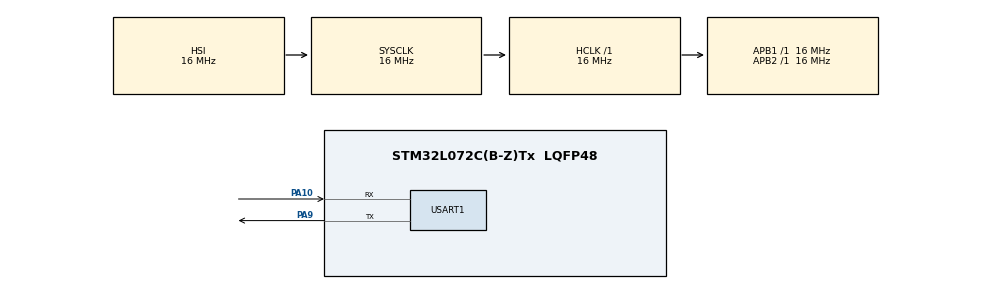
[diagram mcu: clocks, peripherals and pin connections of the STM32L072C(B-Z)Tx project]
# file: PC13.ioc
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Mcu.Family=STM32L0
Mcu.Name=STM32L072C(B-Z)Tx
Mcu.Package=LQFP48
PA10.Mode=Asynchronous
PA10.Signal=USART1_RX
PA9.Mode=Asynchronous
PA9.Signal=USART1_TX
PH0-OSC_IN.Mode=HSE-External-Oscillator
PH0-OSC_IN.Signal=RCC_OSC_IN
PH1-OSC_OUT.Mode=HSE-External-Oscillator
PH1-OSC_OUT.Signal=RCC_OSC_OUT
ProjectManager.HeapSize=0x200
ProjectManager.StackSize=0x400
ProjectManager.TargetToolchain=MDK-ARM V5
RCC.48MEnable=false
RCC.ADCEnable=false
RCC.AHBFreq_Value=16000000
RCC.APB1Freq_Value=16000000
RCC.APB1TimFreq_Value=16000000
RCC.APB2Freq_Value=16000000
RCC.APB2TimFreq_Value=16000000
RCC.ClockTypeHCLK=RCC_CLOCKTYPE_HCLK
RCC.ClockTypePCLK1=RCC_CLOCKTYPE_PCLK1
RCC.ClockTypePCLK2=RCC_CLOCKTYPE_PCLK2
RCC.ClockTypeSysClk=RCC_CLOCKTYPE_SYSCLK
RCC.EnableCSSLSE=false
RCC.EnableHSE=true
RCC.EnableHSELCDDevisor=false
RCC.EnableHSERTCDevisor=false
RCC.EnableLSE=false
RCC.EnableLSERTC=false
RCC.EnbaleCSS=false
RCC.HCLKFreq_Value=16000000
RCC.HSE_VALUE=8000000
RCC.HSI16State=RCC_HSI_ON
RCC.HSI16_VALUE=16000000
RCC.HSI48State=RCC_HSI48_OFF
RCC.HSI48_VALUE=48000000
RCC.HSI_VALUE=16000000
RCC.I2C1Enable=false
RCC.IWDGEnable=false
RCC.LCDEnable=false
RCC.LPTIMEnable=false
RCC.LPUARTEnable=false
RCC.LSE_VALUE=32768
RCC.LSIState=RCC_LSI_OFF
RCC.MCOEnable=false
RCC.MSI_VALUE=2097000
RCC.PLLSource=RCC_PLLSOURCE_HSI
RCC.PLLState=RCC_PLL_OFF
RCC.RCC_PERIPHCLK_USART1Var=RCC_PERIPHCLK_USART1
RCC.RNGEnable=false
RCC.RTCEnable=false
RCC.SYSCLKFreq_VALUE=16000000
RCC.SYSCLKSource=RCC_SYSCLKSOURCE_HSI
RCC.USART1Enable=true
RCC.USART2Enable=false
RCC.USBEnable=false
RCC.VCOOutputFreq_Value=48000000
USART1.HwFlowCtl-Asynchronous=UART_HWCONTROL_NONE
USART1.VirtualMode-Asynchronous=VM_ASYNC
board=PC13

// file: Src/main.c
/**
  ******************************************************************************
  * File Name          : main.c
  * Description        : Main program body
  ******************************************************************************
  *
  * COPYRIGHT(c) 2017 STMicroelectronics
  *
  * Redistribution and use in source and binary forms, with or without modification,
  * are permitted provided that the following conditions are met:
  *   1. Redistributions of source code must retain the above copyright notice,
  *      this list of conditions and the following disclaimer.
  *   2. Redistributions in binary form must reproduce the above copyright notice,
  *      this list of conditions and the following disclaimer in the documentation
  *      and/or other materials provided with the distribution.
  *   3. Neither the name of STMicroelectronics nor the names of its contributors
  *      may be used to endorse or promote products derived from this software
  *      without specific prior written permission.
  *
  * THIS SOFTWARE IS PROVIDED BY THE COPYRIGHT HOLDERS AND CONTRIBUTORS "AS IS"
  * AND ANY EXPRESS OR IMPLIED WARRANTIES, INCLUDING, BUT NOT LIMITED TO, THE
  * IMPLIED WARRANTIES OF MERCHANTABILITY AND FITNESS FOR A PARTICULAR PURPOSE ARE
  * DISCLAIMED. IN NO EVENT SHALL THE COPYRIGHT HOLDER OR CONTRIBUTORS BE LIABLE
  * FOR ANY DIRECT, INDIRECT, INCIDENTAL, SPECIAL, EXEMPLARY, OR CONSEQUENTIAL
  * DAMAGES (INCLUDING, BUT NOT LIMITED TO, PROCUREMENT OF SUBSTITUTE GOODS OR
  * SERVICES; LOSS OF USE, DATA, OR PROFITS; OR BUSINESS INTERRUPTION) HOWEVER
  * CAUSED AND ON ANY THEORY OF LIABILITY, WHETHER IN CONTRACT, STRICT LIABILITY,
  * OR TORT (INCLUDING NEGLIGENCE OR OTHERWISE) ARISING IN ANY WAY OUT OF THE USE
  * OF THIS SOFTWARE, EVEN IF ADVISED OF THE POSSIBILITY OF SUCH DAMAGE.
  *
  ******************************************************************************
  */
#include "main.h"
#include "stm32l0xx_hal.h"
#include "usart.h"
#include "gpio.h"

/* USER CODE BEGIN Includes */

#include "user_standby.h"

/* USER CODE END Includes */

/* USER CODE BEGIN PV */
/* Private variables ---------------------------------------------------------*/
#ifdef __GNUC__
  /* With GCC/RAISONANCE, small printf (option LD Linker->Libraries->Small printf
     set to 'Yes') calls __io_putchar() */
  #define PUTCHAR_PROTOTYPE int __io_putchar(int ch)
#else
  #define PUTCHAR_PROTOTYPE int fputc(int ch, FILE *f)
#endif /* __GNUC__ */

 /**
  * @brief  Retargets the C library printf function to the USART.
  * @param  None
  * @retval None
  */
PUTCHAR_PROTOTYPE
{
  /* Place your implementation of fputc here */
  /* e.g. write a character to the USART */
  HAL_UART_Transmit(&huart1, (uint8_t *)&ch, 1, 0xFFFF);  ///不需要库原因：从速度考虑直接使用寄存器更好
  return 1;
}

/* USER CODE END PV */

void SystemClock_Config(void);
void Error_Handler(void);

/* USER CODE BEGIN PFP */
/* Private function prototypes -----------------------------------------------*/

/* USER CODE END PFP */

int main(void)
{

  /* MCU Configuration----------------------------------------------------------*/

  /* Reset of all peripherals, Initializes the Flash interface and the Systick. */
  HAL_Init();

  /* Configure the system clock */
  SystemClock_Config();

  /* Initialize all configured peripherals */
  MX_GPIO_Init();
  MX_USART1_UART_Init();

  StandbyExitMode( );

  /* USER CODE BEGIN 2 */
  printf("hello world\r\n");
 /* 检测系统是否是从待机模式启动的 */
  if (__HAL_PWR_GET_FLAG(PWR_FLAG_SB) != RESET)
  {
    printf("待机唤醒复位\n");

		if(StandbyCheckPwrkey())  ///读IO信息，无触发中断
		{
			//StandbyInit( );
		  printf("开机\r\n");
			/* 清除待机标志位 */
			__HAL_PWR_CLEAR_FLAG(PWR_FLAG_SB);
//			StandbyExitMode( );  ///中断唤醒后再次初始化PC13外部中断
		}else
		{
				printf("继续休眠\r\n");
			 	StandbyEnterMode( );
		}
  }
  else if(__HAL_RCC_GET_FLAG(RCC_FLAG_SFTRST))
  {
    printf("\n软件复位不重置\n");
   	__HAL_RCC_CLEAR_RESET_FLAGS();
  }
	else
	{
		printf("系统上电休眠\r\n");
		StandbyEnterMode( );
	}

  /* USER CODE END 2 */

  /* Infinite loop */
  while (1)
  {

  /* USER CODE BEGIN 3 */
		printf("hello world123\r\n");
		HAL_Delay(500);

  }
  /* USER CODE END 3 */

}

/** System Clock Configuration
*/
void SystemClock_Config(void)
{

  RCC_OscInitTypeDef RCC_OscInitStruct;
  RCC_ClkInitTypeDef RCC_ClkInitStruct;
  RCC_PeriphCLKInitTypeDef PeriphClkInit;

    /**Configure the main internal regulator output voltage
    */
  __HAL_PWR_VOLTAGESCALING_CONFIG(PWR_REGULATOR_VOLTAGE_SCALE1);

    /**Initializes the CPU, AHB and APB busses clocks
    */
  RCC_OscInitStruct.OscillatorType = RCC_OSCILLATORTYPE_HSI;
  RCC_OscInitStruct.HSIState = RCC_HSI_ON;
  RCC_OscInitStruct.HSICalibrationValue = 16;
  RCC_OscInitStruct.PLL.PLLState = RCC_PLL_NONE;
  if (HAL_RCC_OscConfig(&RCC_OscInitStruct) != HAL_OK)
  {
    Error_Handler();
  }

    /**Initializes the CPU, AHB and APB busses clocks
    */
  RCC_ClkInitStruct.ClockType = RCC_CLOCKTYPE_HCLK|RCC_CLOCKTYPE_SYSCLK
                              |RCC_CLOCKTYPE_PCLK1|RCC_CLOCKTYPE_PCLK2;
  RCC_ClkInitStruct.SYSCLKSource = RCC_SYSCLKSOURCE_HSI;
  RCC_ClkInitStruct.AHBCLKDivider = RCC_SYSCLK_DIV1;
  RCC_ClkInitStruct.APB1CLKDivider = RCC_HCLK_DIV1;
  RCC_ClkInitStruct.APB2CLKDivider = RCC_HCLK_DIV1;

  if (HAL_RCC_ClockConfig(&RCC_ClkInitStruct, FLASH_LATENCY_0) != HAL_OK)
  {
    Error_Handler();
  }

  PeriphClkInit.PeriphClockSelection = RCC_PERIPHCLK_USART1;
  PeriphClkInit.Usart1ClockSelection = RCC_USART1CLKSOURCE_PCLK2;
  if (HAL_RCCEx_PeriphCLKConfig(&PeriphClkInit) != HAL_OK)
  {
    Error_Handler();
  }

    /**Configure the Systick interrupt time
    */
  HAL_SYSTICK_Config(HAL_RCC_GetHCLKFreq()/1000);

    /**Configure the Systick
    */
  HAL_SYSTICK_CLKSourceConfig(SYSTICK_CLKSOURCE_HCLK);

  /* SysTick_IRQn interrupt configuration */
  HAL_NVIC_SetPriority(SysTick_IRQn, 0, 0);
}

/* USER CODE BEGIN 4 */
/**
  * 函数功能: 按键外部中断服务函数
  * 输入参数: GPIO_Pin：中断引脚
  * 返 回 值: 无
  * 说    明: 无
  */
void HAL_GPIO_EXTI_Callback(uint16_t GPIO_Pin)
{
  if(GPIO_Pin==PWR_KEY_PIN)
  {
    printf("\n EXTI13中断 \n");
   if(StandbyCheckPwrkey())
   {
		 printf("关机 \r\n");
     StandbyEnterMode();
   }
	 else
		 printf("意外中断\r\n");
  }
}
/* USER CODE END 4 */

void Error_Handler(void)
{
  while(1)
  {
  }
}

/************************ (C) COPYRIGHT STMicroelectronics *****END OF FILE****/
